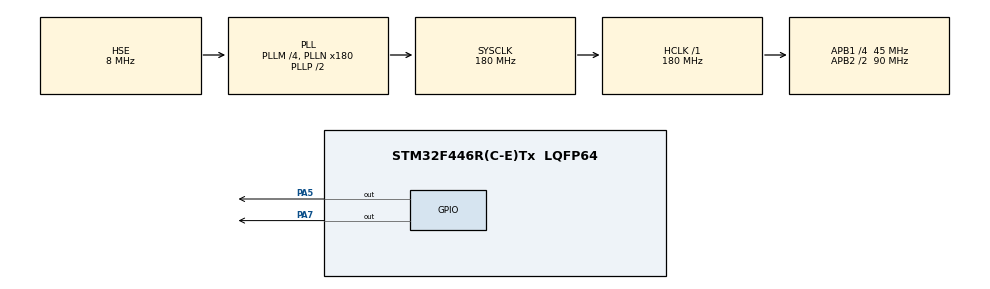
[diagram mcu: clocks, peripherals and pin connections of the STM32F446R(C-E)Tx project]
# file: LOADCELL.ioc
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Mcu.Family=STM32F4
Mcu.Name=STM32F446R(C-E)Tx
Mcu.Package=LQFP64
NVIC.PriorityGroup=NVIC_PRIORITYGROUP_0
PA13.Mode=Serial_Wire
PA13.Signal=SYS_JTMS-SWDIO
PA14.Mode=Serial_Wire
PA14.Signal=SYS_JTCK-SWCLK
PA5.Signal=GPIO_Output
PA7.Signal=GPIO_Output
PH0-OSC_IN.Mode=HSE-External-Oscillator
PH0-OSC_IN.Signal=RCC_OSC_IN
PH1-OSC_OUT.Mode=HSE-External-Oscillator
PH1-OSC_OUT.Signal=RCC_OSC_OUT
ProjectManager.HeapSize=0x200
ProjectManager.StackSize=0x400
ProjectManager.TargetToolchain=MDK-ARM V5.27
RCC.AHBFreq_Value=180000000
RCC.APB1CLKDivider=RCC_HCLK_DIV4
RCC.APB1Freq_Value=45000000
RCC.APB1TimFreq_Value=90000000
RCC.APB2CLKDivider=RCC_HCLK_DIV2
RCC.APB2Freq_Value=90000000
RCC.APB2TimFreq_Value=180000000
RCC.CortexFreq_Value=180000000
RCC.FLatency-AdvancedSettings=FLASH_LATENCY_5
RCC.HCLKFreq_Value=180000000
RCC.HSE_VALUE=8000000
RCC.HSI_VALUE=16000000
RCC.LSE_VALUE=32768
RCC.PLLM=4
RCC.PLLN=180
RCC.PLLSourceVirtual=RCC_PLLSOURCE_HSE
RCC.SYSCLKFreq_VALUE=180000000
RCC.SYSCLKSource=RCC_SYSCLKSOURCE_PLLCLK
RCC.USBFreq_Value=180000000
RCC.VCOOutputFreq_Value=360000000
board=NUCLEO-F446RE

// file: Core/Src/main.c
/* USER CODE BEGIN Header */
/**
  ******************************************************************************
  * @file           : main.c
  * @brief          : Main program body
  ******************************************************************************
  * @attention
  *
  * <h2><center>&copy; Copyright (c) 2021 STMicroelectronics.
  * All rights reserved.</center></h2>
  *
  * This software component is licensed by ST under BSD 3-Clause license,
  * the "License"; You may not use this file except in compliance with the
  * License. You may obtain a copy of the License at:
  *                        opensource.org/licenses/BSD-3-Clause
  *
  ******************************************************************************
  */
/* USER CODE END Header */
#include "main.h"
#include "gpio.h"

/* USER CODE BEGIN Includes */
#include "stdbool.h"
#include "hx711.h"
/* USER CODE END Includes */

/* USER CODE BEGIN PV */
float yuzgramdakazanc = 71.93f;								//	20kg	131.2f			100kg	48
float gram_degisim_ofset = 5;									// 	bu degisken kadar degisim varsa azalma durumunu kontrol eder agirlik sensörü ile alakasi yok
float olculen_agirlik=0;

		int ara_ofset=0;
		int ara_olcum=0;

	float ara_ofset2=0;
	float kalibre_agirligi=180;	// sim gram

	HX711 HX711_test;

/* USER CODE END PV */

void SystemClock_Config(void);
/* USER CODE BEGIN PFP */
void Kalibrasyon(){

	HX711_test.offset=ara_ofset;							 			// baslangiç degeri varsa araofset o olsun

		 for (int i = 0; i < 25; i++)								// 25 adet örnek alip ortalamasini aliyoruz
    {
      ara_ofset += HX711_Value(HX711_test);
			HAL_Delay(100);
    }
		HX711_test.offset = ara_ofset / 25;						// artik yeni offset degerini girmis olduk

		ara_ofset = 0 ;															// bu aradegeri tekrar kullanacagiz

		for (int i = 0; i < 25; i++)
    {
      ara_ofset += HX711_Value(HX711_test);
			HAL_Delay(100);
    }

		ara_ofset2 = ara_ofset / 25;

		yuzgramdakazanc = ara_ofset2 / kalibre_agirligi;

}
/* USER CODE END PFP */

int main(void)
{

  /* MCU Configuration--------------------------------------------------------*/

  /* Reset of all peripherals, Initializes the Flash interface and the Systick. */
  HAL_Init();
 MX_GPIO_Init();

  /* Configure the system clock */
  SystemClock_Config();

  /* USER CODE BEGIN SysInit */
	HX711_test.gain = 128;
	HX711_test.gpioData = GPIOA;
	HX711_test.pinData = GPIO_PIN_5;
	HX711_test.gpioSck = GPIOA;
	HX711_test.pinSck = GPIO_PIN_7;
	HX711_test.offset = 16497659;

	   HX711_Init(HX711_test);
	// bos agirlikla bu

//		 for (int i = 0; i < 25; i++)
//    {
//      ara_ofset += HX711_Value(HX711_test);
//			HAL_Delay(100);
//    }
//		HX711_test.offset = ara_ofset / 25;

// kalibre agirligi ile bu

		for (int i = 0; i < 25; i++)
    {
      ara_ofset += HX711_Value(HX711_test);
			HAL_Delay(100);
    }

		ara_ofset2 = ara_ofset / 25;

		yuzgramdakazanc = ara_ofset2 / kalibre_agirligi;

   olculen_agirlik=0;

  /* USER CODE END SysInit */

  /* Initialize all configured peripherals */

  /* Infinite loop */
  while (1)
  {

    /* USER CODE BEGIN 3 */

	// measuring weight
			olculen_agirlik = HX711_Value(HX711_test);
			HAL_Delay(100);

  }
  /* USER CODE END 3 */
}

void SystemClock_Config(void)
{
  RCC_OscInitTypeDef RCC_OscInitStruct = {0};
  RCC_ClkInitTypeDef RCC_ClkInitStruct = {0};

  /** Configure the main internal regulator output voltage
  */
  __HAL_RCC_PWR_CLK_ENABLE();
  __HAL_PWR_VOLTAGESCALING_CONFIG(PWR_REGULATOR_VOLTAGE_SCALE1);
  /** Initializes the RCC Oscillators according to the specified parameters
  * in the RCC_OscInitTypeDef structure.
  */
  RCC_OscInitStruct.OscillatorType = RCC_OSCILLATORTYPE_HSE;
  RCC_OscInitStruct.HSEState = RCC_HSE_ON;
  RCC_OscInitStruct.PLL.PLLState = RCC_PLL_ON;
  RCC_OscInitStruct.PLL.PLLSource = RCC_PLLSOURCE_HSE;
  RCC_OscInitStruct.PLL.PLLM = 4;
  RCC_OscInitStruct.PLL.PLLN = 180;
  RCC_OscInitStruct.PLL.PLLP = RCC_PLLP_DIV2;
  RCC_OscInitStruct.PLL.PLLQ = 2;
  RCC_OscInitStruct.PLL.PLLR = 2;
  if (HAL_RCC_OscConfig(&RCC_OscInitStruct) != HAL_OK)
  {
    Error_Handler();
  }
  /** Activate the Over-Drive mode
  */
  if (HAL_PWREx_EnableOverDrive() != HAL_OK)
  {
    Error_Handler();
  }
  /** Initializes the CPU, AHB and APB buses clocks
  */
  RCC_ClkInitStruct.ClockType = RCC_CLOCKTYPE_HCLK|RCC_CLOCKTYPE_SYSCLK
                              |RCC_CLOCKTYPE_PCLK1|RCC_CLOCKTYPE_PCLK2;
  RCC_ClkInitStruct.SYSCLKSource = RCC_SYSCLKSOURCE_PLLCLK;
  RCC_ClkInitStruct.AHBCLKDivider = RCC_SYSCLK_DIV1;
  RCC_ClkInitStruct.APB1CLKDivider = RCC_HCLK_DIV4;
  RCC_ClkInitStruct.APB2CLKDivider = RCC_HCLK_DIV2;

  if (HAL_RCC_ClockConfig(&RCC_ClkInitStruct, FLASH_LATENCY_5) != HAL_OK)
  {
    Error_Handler();
  }
}

void Error_Handler(void)
{
  __disable_irq();
  while (1)
  {
  }
}

/************************ (C) COPYRIGHT STMicroelectronics *****END OF FILE****/
